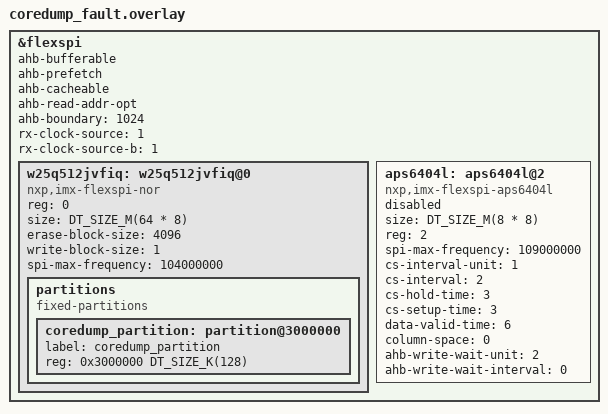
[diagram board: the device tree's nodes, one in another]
/*
 * Copyright 2025 NXP
 *
 * SPDX-License-Identifier: BSD-3-Clause
 */

&flexspi {
	status = "okay";
	ahb-bufferable;
	ahb-prefetch;
	ahb-cacheable;
	ahb-read-addr-opt;
	ahb-boundary = "1024";
	rx-clock-source = <1>;
	rx-clock-source-b = <1>;
	/* Winbond external flash */
	w25q512jvfiq: w25q512jvfiq@0 {
		compatible = "nxp,imx-flexspi-nor";
		reg = <0>;
		size = <DT_SIZE_M(64 * 8)>;
		status = "okay";
		erase-block-size = <4096>;
		write-block-size = <1>;
		spi-max-frequency = <104000000>;
		partitions {
			compatible = "fixed-partitions";
			#address-cells = <1>;
			#size-cells = <1>;

			coredump_partition: partition@3000000 {
				label = "coredump_partition";
				reg = <0x3000000 DT_SIZE_K(128)>;
			};
		};
	};
	aps6404l: aps6404l@2 {
			compatible = "nxp,imx-flexspi-aps6404l";
			/* APS6404L is 8MB, 64MBit pSRAM */
			size = <DT_SIZE_M(8 * 8)>;
			reg = <2>;
			spi-max-frequency = <109000000>;
			/* PSRAM cannot be enabled while board is in default XIP
			 * configuration, as it will conflict with flash chip.
			 */
			status = "disabled";
			cs-interval-unit = <1>;
			cs-interval = <2>;
			cs-hold-time = <3>;
			cs-setup-time = <3>;
			data-valid-time = <6>;
			column-space = <0>;
			ahb-write-wait-unit = <2>;
			ahb-write-wait-interval = <0>;
	};
};
